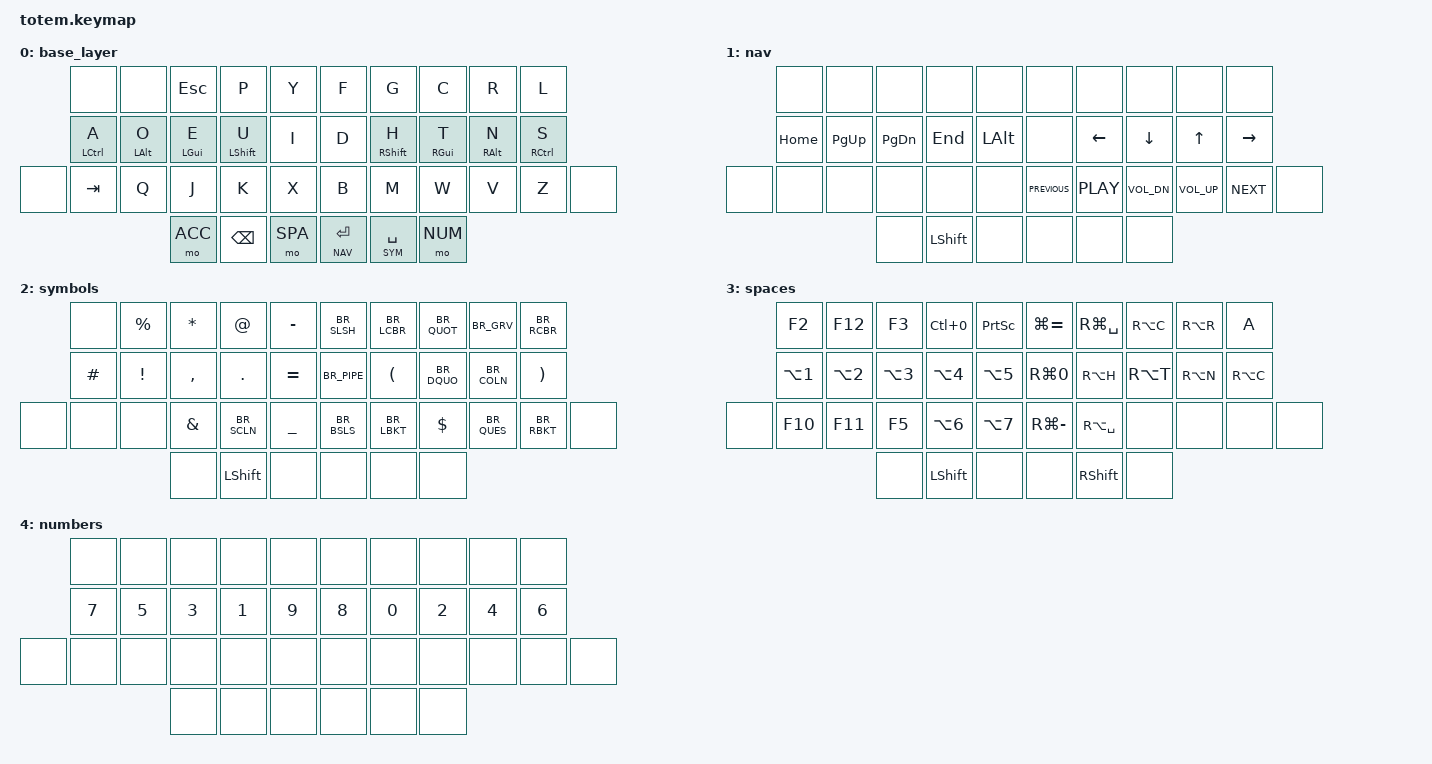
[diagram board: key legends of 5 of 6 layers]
#include <behaviors.dtsi>
#include <dt-bindings/zmk/bt.h>
#include <dt-bindings/zmk/keys.h>
#include "br.h"

#define NAV 1
#define SYM 2
#define SPA 3
#define NUM 4
#define ACC 5

&mt {
    quick-tap-ms = <100>;
    global-quick-tap;
    flavor = "tap-preferred";
    tapping-term-ms = <170>;
};

/ {
    keymap {
        compatible = "zmk,keymap";

        base_layer {
            /*

             +-----+-----+-----+-----+-----+      +-----+-----+-----+-----+-----+
             |     |     | ESC |  p  |  y  |      |  f  |  g  |  c  |  r  |  l  |
             +-----+-- ---+-----+-----+-----+      +-----+-----+-----+-----+-----+
             |  a  |  o  |  e  |  u  |  i  |      |  d  |  h  |  t  |  n  |  s  |
             | CTR | NAV | CMD | SFT | ALT |      | ALT | SFT | CMD | NAV | CTR |
             +-----+-----+-----+-----+-----+      +-----+-----+-----+-----+-----+
             | TAB |  q  |  j  |  k  |  x  |      |  b  |  m  |  w  |  v  |  z  |
             +-----+-----+-----+-----+-----+      +-----+-----+-----+-----+-----+
                         |  #  | BSP | SPA |      | ENT | _|$ |  #  |
                         +-----+-----+-----+      +-----+-----+-----+
*/

            bindings = <
        &none        &none       &kp ESCAPE  &kp P        &kp Y                   &kp F          &kp G          &kp C       &kp R       &kp L
        &mt LCTRL A  &mt LALT O  &mt LGUI E  &mt LSHFT U  &kp I                   &kp D          &mt RSHFT H    &mt RGUI T  &mt RALT N  &mt RCTRL S
&none   &kp TAB      &kp Q       &kp J       &kp K        &kp X                   &kp B          &kp M          &kp W       &kp V       &kp Z       &none
                                 &mo ACC     &kp BSPC     &mo SPA                 &lt NAV ENTER  &lt SYM SPACE  &mo NUM
            >;
        };

        nav {
            /*
             +-----+-----+-----+-----+-----+      +-----+-----+-----+-----+-----+
             |     |     |     |     |     |      |     |     |     |     |     |
             +-----+-----+-----+-----+-----+      +-----+-----+-----+-----+-----+
             | HME | PUP | PDN | END | ALT |      |     |  ←  |  ↓  |  ↑  |  →  |
             +-----+-----+-----+-----+-----+      +-----+-----+-----+-----+-----+
             |     |     |     |     |     |      |  << |  ▸  |  )  | ))) |  >> |
             +-----+-----+-----+-----+-----+      +-----+-----+-----+-----+-----+
                         |  _  | SFT |  _  |      |  _  |  _  |  _  |
                         +-----+-----+-----+      +-----+-----+-----+
*/

            bindings = <
       &none     &none        &none          &none           &none               &none           &none       &none         &none         &none
       &kp HOME  &kp PAGE_UP  &kp PAGE_DOWN  &kp END         &kp LEFT_ALT        &none           &kp LEFT    &kp DOWN      &kp UP        &kp RIGHT
&none  &none     &none        &none          &none           &none               &kp C_PREVIOUS  &kp C_PLAY  &kp C_VOL_DN  &kp C_VOL_UP  &kp C_NEXT  &none
                              &none          &kp LEFT_SHIFT  &none               &none           &none       &none
            >;
        };

        symbols {
            /*
             +-----+-----+-----+-----+-----+      +-----+-----+-----+-----+-----+
             |     |  %  |  *  |  @  |  -  |      |  /  |  {  |  '  |  `  |  }  |
             +-----+-----+-----+-----+-----+      +-----+-----+-----+-----+-----+
             |  #  |  !  |  ,  |  .  |  =  |      |  |  |  (  |  "  |  :  |  )  |
             +-----+-----+-----+-----+-----+      +-----+-----+-----+-----+-----+
             |     |     |  &  |  ;  |  _  |      |  \  |  [  |  $  |  ?  |  ]  |
             +-----+-----+-----+-----+-----+      +-----+-----+-----+-----+-----+
                         |  _  | SFT |  _  |      |  _  |  _  |  _  |
                         +-----+-----+-----+      +-----+-----+-----+
*/

            bindings = <
       &none     &kp PERCENT  &kp STAR  &kp AT          &kp MINUS                &kp BR_SLSH  &kp BR_LCBR  &kp BR_QUOT  &kp BR_GRV   &kp BR_RCBR
       &kp HASH  &kp EXCL     &kp COMMA &kp DOT         &kp EQUAL                &kp BR_PIPE  &kp LPAR     &kp BR_DQUO  &kp BR_COLN  &kp RPAR
&none  &none     &none        &kp AMPS  &kp BR_SCLN     &kp UNDER                &kp BR_BSLS  &kp BR_LBKT  &kp DOLLAR   &kp BR_QUES  &kp BR_RBKT    &none
                              &none     &kp LEFT_SHIFT  &none                    &none        &none        &none
            >;
        };

        spaces {
            /*
             +-----+-----+-----+-----+-----+      +-----+-----+-----+-----+-----+
             |  F2 | F12 | F3  | CT0 |PRINT|      | ZIN | RUN | ←[  |  ]→ |     |
             +-----+-----+-----+-----+-----+      +-----+-----+-----+-----+-----+
             |  1  |  2  |  3  |  4  |  5  |      | Z0  |  ←  |  ↑  |  ↓  |  →  |
             +-----+-----+-----+-----+-----+      +-----+-----+-----+-----+-----+
             | F10 | F11 |  F5 |  6  |  7  |      | ZOU | CYL |     |     |     |
             +-----+-----+-----+-----+-----+      +-----+-----+-----+-----+-----+
                         |  _  | SFT |  _  |      |  _  | SFT |  _  |
                         +-----+-----+-----+      +-----+-----+-----+
*/

            bindings = <
        &kp F2      &kp F12     &kp F3      &kp LC(N0)  &kp PRINTSCREEN           &kp LG(EQUAL)  &kp RG(SPACE)    &kp RA(C)  &kp RA(R)  &kp A
        &kp LA(N1)  &kp LA(N2)  &kp LA(N3)  &kp LA(N4)  &kp LA(N5)                &kp RG(N0)     &kp RA(H)        &kp RA(T)  &kp RA(N)  &kp RA(C)
&none   &kp F10     &kp F11     &kp F5      &kp LA(N6)  &kp LA(N7)                &kp RG(MINUS)  &kp RA(SPACE)    &none      &none      &none      &none
                                &none       &kp LSHFT   &none                     &none          &kp RIGHT_SHIFT  &none
            >;
        };

        numbers {
            /*
             +-----+-----+-----+-----+-----+      +-----+-----+-----+-----+-----+
             |     |     |     |     |     |      |     |     |     |     |     |
             +-----+-----+-----+-----+-----+      +-----+-----+-----+-----+-----+
             |  7  |  5  |  3  |  1  |  9  |      |  8  |  0  |  2  |  4  |  6  |
             +-----+-----+-----+-----+-----+      +-----+-----+-----+-----+-----+
             |     |     |     |     |     |      |     |     |     |     |     |
             +-----+-----+-----+-----+-----+      +-----+-----+-----+-----+-----+
                         |  _  |  _  |  _  |      |  _  |  _  |  _  |
                         +-----+-----+-----+      +-----+-----+-----+
*/

            bindings = <
        &none   &none    &none   &none   &none        &none   &none   &none   &none &none
        &kp N7  &kp N5   &kp N3  &kp N1  &kp N9       &kp N8  &kp N0  &kp N2  &kp N4          &kp N6
&none   &none   &none    &none   &none   &none        &none   &none   &none   &none           &none        &none
                         &none   &none   &none        &none   &none   &none
            >;
        };

        accents {
            /*
             +-----+-----+-----+-----+-----+      +-----+-----+-----+-----+-----+
             |     |     |     |     |     |      |     |     |     |     |     |
             +-----+-----+-----+-----+-----+      +-----+-----+-----+-----+-----+
             |     |  Ç  |  ¨  |  ´  |     |      |     |  `  |  ^  |  ~  |     |
             +-----+-----+-----+-----+-----+      +-----+-----+-----+-----+-----+
             |     |     |     |     |     |      |     |     |     |     |     |
             +-----+-----+-----+-----+-----+      +-----+-----+-----+-----+-----+
                         |  _  |  _  |  _  |      |  _  |  _  |  _  |
                         +-----+-----+-----+      +-----+-----+-----+
*/

            bindings = <
        &none   &none         &none        &none         &none        &none   &none        &none         &none         &none
        &none   &kp BR_CCED   &kp BR_DIAE  &kp BR_ACUT   &none        &none   &kp BR_GRV   &kp BR_CIRC   &kp BR_TILD   &none
&none   &none   &none         &none        &none         &none        &none   &none        &none         &none         &none    &none
                              &none        &none         &none        &none   &none
            >;
        };
    };
};
